VERSION ""

BS_:

BU_:

BO_ 0 Throttle_Init_message: 8 Vector__XXX

BO_ 513 CommandThrottle: 8 Vector__XXX
 SG_ Throttlevalue : 0|16@1+ (1,0) [0|65535] "" Vector__XXX

BO_ 385 Throttle_Status: 0 Vector__XXX

BO_ 1793 AcceleratorFeedback: 0 Vector__XXX

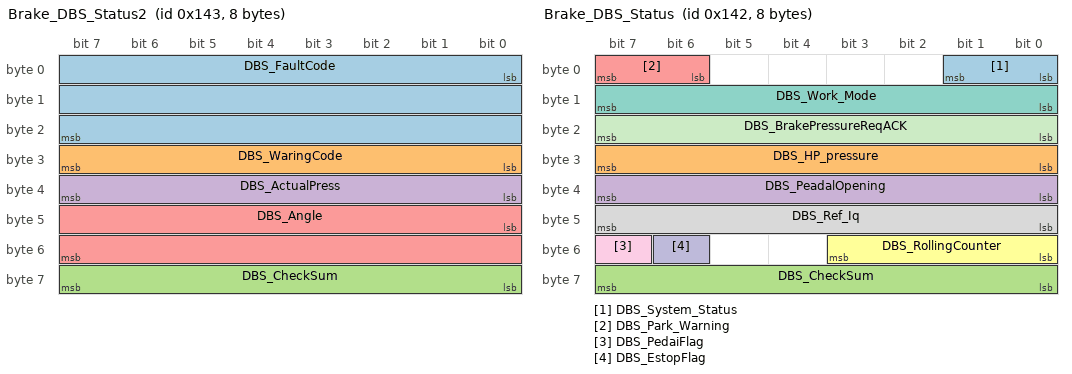
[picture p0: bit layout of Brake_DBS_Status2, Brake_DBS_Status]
BO_ 323 Brake_DBS_Status2: 8 Vector__XXX
 SG_ DBS_FaultCode : 0|24@1+ (0,0) [0|0] "" Vector__XXX
 SG_ DBS_WaringCode : 24|8@1+ (0,0) [0|0] "" Vector__XXX
 SG_ DBS_CheckSum : 56|8@1+ (0,0) [0|0] "" Vector__XXX
 SG_ DBS_ActualPress : 32|8@1+ (0,0) [0|0] "Mpa" Vector__XXX
 SG_ DBS_Angle : 40|16@1+ (0,0) [0|0] "" Vector__XXX

BO_ 322 Brake_DBS_Status: 8 Vector__XXX
 SG_ DBS_System_Status : 0|2@1+ (0,0) [0|0] "N/A" Vector__XXX
 SG_ DBS_HP_pressure : 24|8@1+ (0,0) [0|0] "Mpa" Vector__XXX
 SG_ DBS_CheckSum : 56|8@1+ (0,0) [0|0] "1" Vector__XXX
 SG_ DBS_PeadalOpening : 32|8@1+ (0,0) [0|0] "%" Vector__XXX
 SG_ DBS_Park_Warning : 6|2@1+ (0,0) [0|0] "1" Vector__XXX
 SG_ DBS_RollingCounter : 48|4@1+ (0,0) [0|0] "1" Vector__XXX
 SG_ DBS_Work_Mode : 8|8@1+ (0,0) [0|0] "1" Vector__XXX
 SG_ DBS_Ref_Iq : 40|8@1+ (0,-20) [-20|-20] "0" Vector__XXX
 SG_ DBS_PedaiFlag : 55|1@1- (0,0) [0|0] "1" Vector__XXX
 SG_ DBS_EstopFlag : 54|1@1- (0,0) [0|0] "1" Vector__XXX
 SG_ DBS_BrakePressureReqACK : 16|8@1+ (0,0) [0|0] "1" Vector__XXX

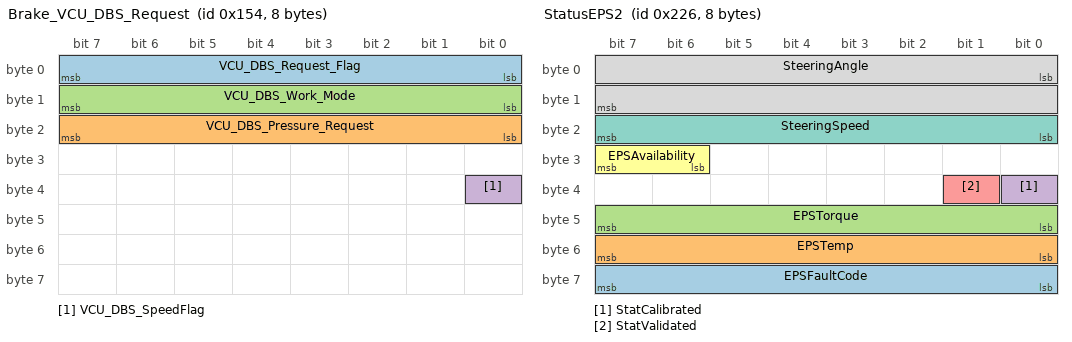
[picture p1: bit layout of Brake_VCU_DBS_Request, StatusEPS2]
BO_ 340 Brake_VCU_DBS_Request: 8 Vector__XXX
 SG_ VCU_DBS_Request_Flag : 0|8@1+ (0,0) [0|0] "1" Vector__XXX
 SG_ VCU_DBS_Pressure_Request : 16|8@1+ (0,0) [0|0] "Mpa" Vector__XXX
 SG_ VCU_DBS_Work_Mode : 8|8@1+ (0,0) [0|0] "1" Vector__XXX
 SG_ VCU_DBS_SpeedFlag : 32|1@1- (0,0) [0|0] "1" Vector__XXX

BO_ 1664 ConfigurationEPS1: 8 Vector__XXX
 SG_ Centering : 0|1@1- (1,0) [0|1] "" Vector__XXX

BO_ 550 StatusEPS2: 8 Vector__XXX
 SG_ EPSFaultCode : 56|8@1+ (1,0) [0|255] "" Vector__XXX
 SG_ EPSTemp : 55|8@0+ (1,-40) [-40|125] "deg" Vector__XXX
 SG_ EPSTorque : 40|8@1+ (1,-100) [-100|100] "" Vector__XXX
 SG_ StatCalibrated : 32|1@1- (1,0) [0|1] "" Vector__XXX
 SG_ StatValidated : 33|1@1- (1,0) [0|1] "" Vector__XXX
 SG_ EPSAvailability : 30|2@1+ (1,0) [0|3] "" Vector__XXX
 SG_ SteeringSpeed : 16|8@1+ (1,0) [0|255] "" Vector__XXX
 SG_ SteeringAngle : 0|16@1+ (1,-7799) [-7799|57736] "" Vector__XXX

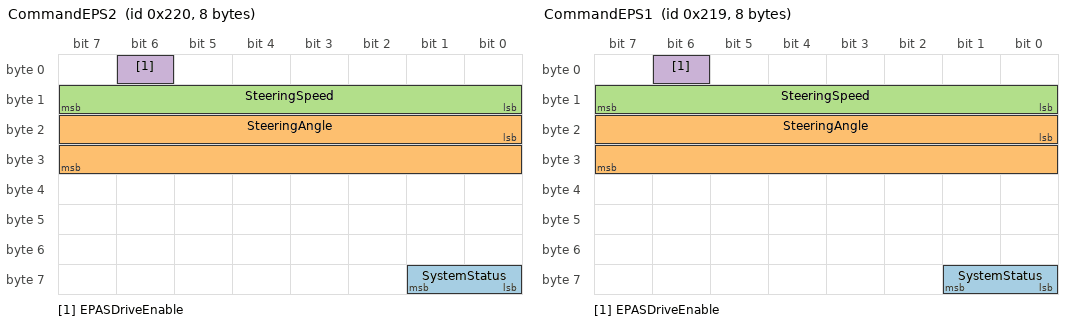
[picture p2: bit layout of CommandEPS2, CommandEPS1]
BO_ 544 CommandEPS2: 8 Vector__XXX
 SG_ SystemStatus : 56|2@1+ (1,0) [0|3] "" Vector__XXX
 SG_ SteeringAngle : 16|16@1+ (1,-7799) [-7799|57736] "" Vector__XXX
 SG_ SteeringSpeed : 8|8@1+ (1,0) [0|255] "" Vector__XXX
 SG_ EPASDriveEnable : 6|1@1- (1,0) [0|1] "" Vector__XXX

BO_ 537 CommandEPS1: 8 Vector__XXX
 SG_ SystemStatus : 56|2@1+ (1,0) [0|3] "" Vector__XXX
 SG_ SteeringAngle : 16|16@1+ (1,-7799) [-7799|57736] "" Vector__XXX
 SG_ SteeringSpeed : 8|8@1+ (1,0) [0|255] "" Vector__XXX
 SG_ EPASDriveEnable : 6|1@1- (1,0) [0|1] "" Vector__XXX

BO_ 1665 ConfigurationEPS2: 8 Vector__XXX

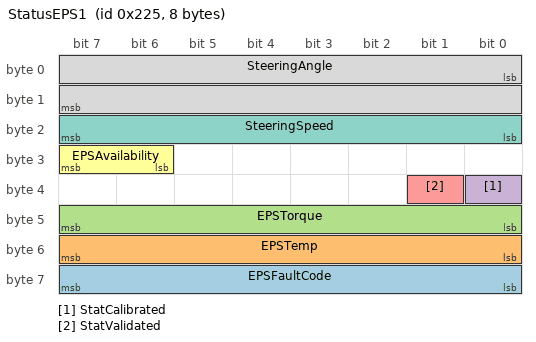
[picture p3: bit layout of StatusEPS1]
BO_ 549 StatusEPS1: 8 Vector__XXX
 SG_ EPSFaultCode : 56|8@1+ (1,0) [0|255] "" Vector__XXX
 SG_ EPSTemp : 55|8@0+ (1,-40) [-40|125] "deg" Vector__XXX
 SG_ EPSTorque : 40|8@1+ (1,-100) [-100|100] "" Vector__XXX
 SG_ StatCalibrated : 32|1@1- (1,0) [0|1] "" Vector__XXX
 SG_ StatValidated : 33|1@1- (1,0) [0|1] "" Vector__XXX
 SG_ EPSAvailability : 30|2@1+ (1,0) [0|3] "" Vector__XXX
 SG_ SteeringSpeed : 16|8@1+ (1,0) [0|255] "" Vector__XXX
 SG_ SteeringAngle : 0|16@1+ (1,-7799) [-7799|57736] "" Vector__XXX
